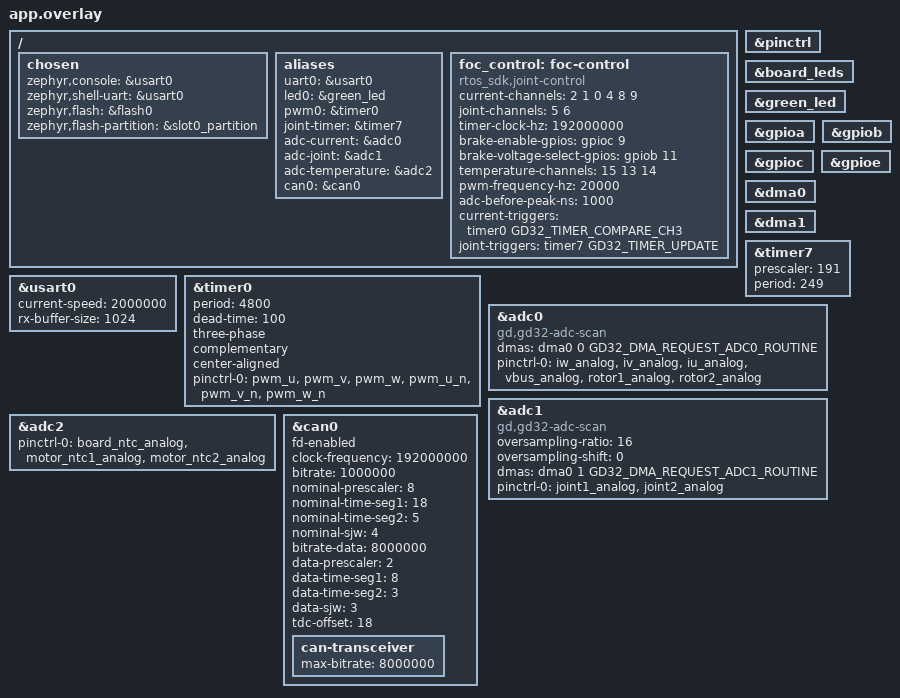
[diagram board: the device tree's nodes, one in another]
#include <dt-bindings/gpio/gpio.h>
#include <dt-bindings/pwm/gd32-timer.h>

&pinctrl { status = "okay"; };
&board_leds { status = "okay"; };
&green_led { status = "okay"; };
&gpioa { status = "okay"; };
&gpiob { status = "okay"; };
&gpioc { status = "okay"; };
&gpioe { status = "okay"; };
&dma0 { status = "okay"; };
&dma1 { status = "okay"; };
&usart0 { status = "okay"; current-speed = <2000000>; rx-buffer-size = <1024>; };
&timer0 {
    #trigger-cells = <1>;
    status = "okay";
    period = <4800>;
    dead-time = <100>;
    three-phase;
    complementary;
    center-aligned;
    pinctrl-0 = <&pwm_u &pwm_v &pwm_w &pwm_u_n &pwm_v_n &pwm_w_n>;
    pinctrl-names = "default";
};
&timer7 {
    #trigger-cells = <1>;
    status = "okay";
    prescaler = <191>;
    period = <249>;
};
&adc0 {
    status = "okay";
    compatible = "gd,gd32-adc-scan", "gd,gd32-adc";
    dmas = <&dma0 0 GD32_DMA_REQUEST_ADC0_ROUTINE>;
    dma-names = "rx";
    pinctrl-0 = <&iw_analog &iv_analog &iu_analog &vbus_analog &rotor1_analog &rotor2_analog>;
    pinctrl-names = "default";
};
&adc1 {
    status = "okay";
    compatible = "gd,gd32-adc-scan", "gd,gd32-adc";
    oversampling-ratio = <16>;
    oversampling-shift = <0>;
    dmas = <&dma0 1 GD32_DMA_REQUEST_ADC1_ROUTINE>;
    dma-names = "rx";
    pinctrl-0 = <&joint1_analog &joint2_analog>;
    pinctrl-names = "default";
};
&adc2 {
    status = "okay";
    pinctrl-0 = <&board_ntc_analog &motor_ntc1_analog &motor_ntc2_analog>;
    pinctrl-names = "default";
};
&can0 {
    status = "okay";
    fd-enabled;
    clock-frequency = <192000000>;
    bitrate = <1000000>;
    nominal-prescaler = <8>;
    nominal-time-seg1 = <18>;
    nominal-time-seg2 = <5>;
    nominal-sjw = <4>;
    bitrate-data = <8000000>;
    data-prescaler = <2>;
    data-time-seg1 = <8>;
    data-time-seg2 = <3>;
    data-sjw = <3>;
    tdc-offset = <18>;

    /* This configuration requires a transceiver rated for 8 Mbit/s. */
    can-transceiver { max-bitrate = <8000000>; };
};
/ {
    chosen { zephyr,console = &usart0; zephyr,shell-uart = &usart0;
             zephyr,flash = &flash0; zephyr,flash-partition = &slot0_partition; };
    aliases { uart0 = &usart0; led0 = &green_led; pwm0 = &timer0; joint-timer = &timer7;
              adc-current = &adc0; adc-joint = &adc1; adc-temperature = &adc2; can0 = &can0; };
    foc_control: foc-control {
        compatible = "rtos_sdk,joint-control";
        current-channels = <2 1 0 4 8 9>;
        joint-channels = <5 6>;
        timer-clock-hz = <192000000>;
        brake-enable-gpios = <&gpioc 9 GPIO_ACTIVE_HIGH>;
        brake-voltage-select-gpios = <&gpiob 11 GPIO_ACTIVE_HIGH>;
        temperature-channels = <15 13 14>;
        pwm-frequency-hz = <20000>;
        adc-before-peak-ns = <1000>;
        current-triggers = <&timer0 GD32_TIMER_COMPARE_CH3>;
        joint-triggers = <&timer7 GD32_TIMER_UPDATE>;
    };
};
